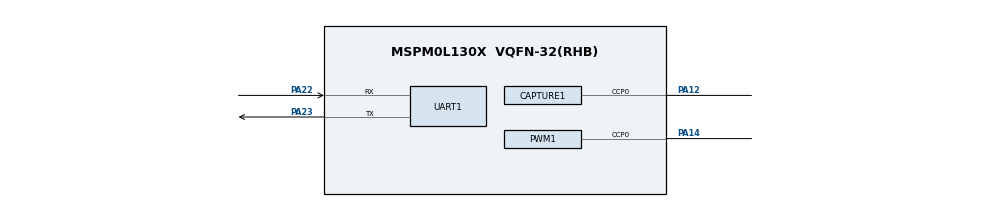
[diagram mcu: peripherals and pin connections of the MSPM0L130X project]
/**
 * @cliArgs --device "MSPM0L130X" --package "VQFN-32(RHB)" --part "Default" --product "mspm0_sdk@1.20.01.06"
 * @versions {"tool":"1.18.0+3266"}
 */

/**
 * Import the modules used in this configuration.
 */
const CAPTURE  = scripting.addModule("/ti/driverlib/CAPTURE", {}, false);
const CAPTURE1 = CAPTURE.addInstance();
const GPIO     = scripting.addModule("/ti/driverlib/GPIO", {}, false);
const GPIO1    = GPIO.addInstance();
const PWM      = scripting.addModule("/ti/driverlib/PWM", {}, false);
const PWM1     = PWM.addInstance();
const SYSCTL   = scripting.addModule("/ti/driverlib/SYSCTL");
const UART     = scripting.addModule("/ti/driverlib/UART", {}, false);
const UART1    = UART.addInstance();

/**
 * Write custom configuration values to the imported modules.
 */
CAPTURE1.$name                      = "CAPTURE_0";
CAPTURE1.captMode                   = "COMBINED";
CAPTURE1.interrupts                 = ["CC0_DN","CC1_DN","ZERO"];
CAPTURE1.timerPeriod                = "2.048 ms";
CAPTURE1.peripheral.$assign         = "TIMG0";
CAPTURE1.peripheral.ccp0Pin.$assign = "PA12";
CAPTURE1.ccp0PinConfig.$name        = "ti_driverlib_gpio_GPIOPinGeneric1";

const Board = scripting.addModule("/ti/driverlib/Board", {}, false);

GPIO1.$name                         = "GPIO_LEDS";
GPIO1.port                          = "PORTA";
GPIO1.associatedPins[0].$name       = "USER_LED_1";
GPIO1.associatedPins[0].assignedPin = "0";

PWM1.$name                      = "PWM_0";
PWM1.clockDivider               = 8;
PWM1.ccIndex                    = [0];
PWM1.interrupts                 = ["LOAD_EVENT"];
PWM1.clockPrescale              = 256;
PWM1.timerCount                 = 15000;
PWM1.peripheral.$assign         = "TIMG1";
PWM1.peripheral.ccp0Pin.$assign = "PA14";
PWM1.PWM_CHANNEL_0.$name        = "ti_driverlib_pwm_PWMTimerCC0";
PWM1.PWM_CHANNEL_0.dutyCycle    = 50;
PWM1.ccp0PinConfig.$name        = "ti_driverlib_gpio_GPIOPinGeneric0";

SYSCTL.clockTreeEn = true;

UART1.$name                    = "UART_0";
UART1.targetBaudRate           = 115200;
UART1.enabledInterrupts        = ["RX"];
UART1.peripheral.$assign       = "UART0";
UART1.peripheral.rxPin.$assign = "PA22";
UART1.peripheral.txPin.$assign = "PA23";
UART1.txPinConfig.$name        = "ti_driverlib_gpio_GPIOPinGeneric2";
UART1.rxPinConfig.$name        = "ti_driverlib_gpio_GPIOPinGeneric3";

/**
 * Pinmux solution for unlocked pins/peripherals. This ensures that minor changes to the automatic solver in a future
 * version of the tool will not impact the pinmux you originally saw.  These lines can be completely deleted in order to
 * re-solve from scratch.
 */
Board.peripheral.$suggestSolution            = "DEBUGSS";
Board.peripheral.swclkPin.$suggestSolution   = "PA20";
Board.peripheral.swdioPin.$suggestSolution   = "PA19";
GPIO1.associatedPins[0].pin.$suggestSolution = "PA0";
